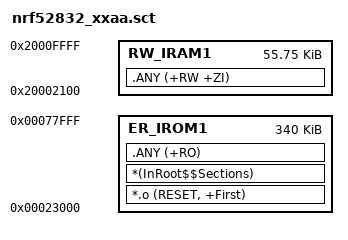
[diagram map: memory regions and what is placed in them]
; *************************************************************
; *** Scatter-Loading Description File generated by uVision ***
; *************************************************************

LR_IROM1 0x00023000 0x00055000  {    ; load region size_region
  ER_IROM1 0x00023000 0x00055000  {  ; load address = execution address
   *.o (RESET, +First)
   *(InRoot$$Sections)
   .ANY (+RO)
  }
  RW_IRAM1 0x20002100 0x0000DF00  {  ; RW data
   .ANY (+RW +ZI)
  }
}

